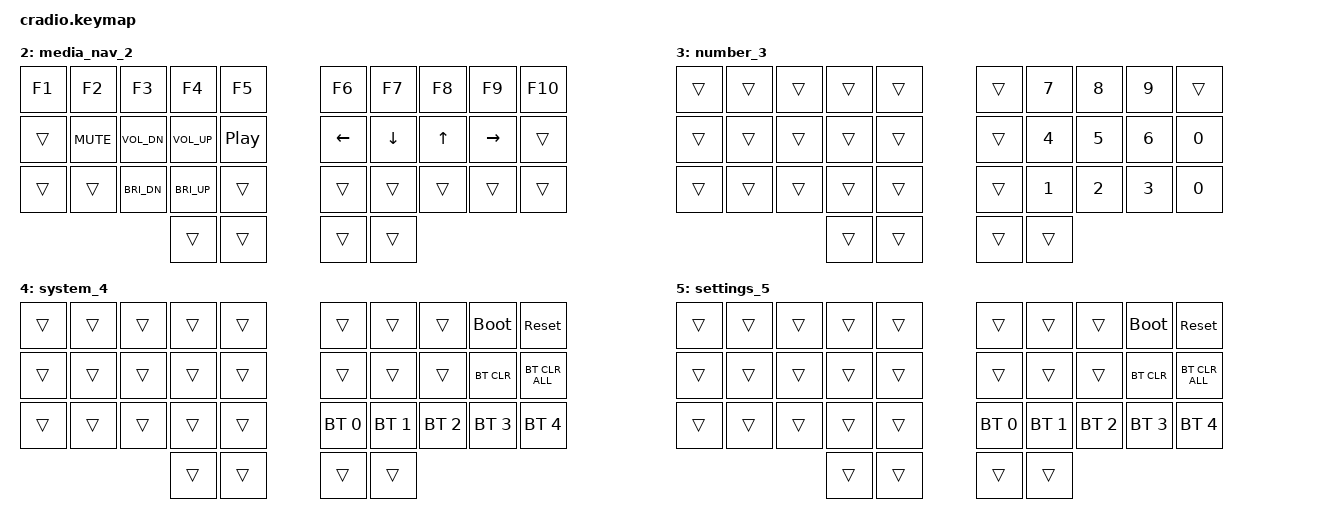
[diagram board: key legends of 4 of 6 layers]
// Copyright (c) 2022 The ZMK Contributors
// SPDX-License-Identifier: MIT

#include <behaviors.dtsi>
#include <dt-bindings/zmk/keys.h>
#include <dt-bindings/zmk/bt.h>

// Home row mods macro
#define HRML(k1,k2,k3,k4,k5) &ht LGUI k1  &ht LCTRL k2  &ht LALT k3  &ht LSHFT k4  &ht LA(LC(LG(LSHFT))) k5
#define HRMR(k1,k2,k3,k4,k5) &ht LA(LC(LG(LSHFT))) k1  &ht LSHFT k2  &ht LALT k3  &ht LCTRL k4  &ht LGUI k5
#define COMBO_0(NAME, BINDINGS, KEYPOS) \
  combo_##NAME { \
    timeout-ms = <50>; \
    bindings = <BINDINGS>; \
    key-positions = <KEYPOS>; \
    layers = <0>; \
  };
#define MACRO(NAME, BINDINGS) \
  macro_##NAME: macro_##NAME { \
    compatible     = "zmk,behavior-macro"; \
    tap-ms         = <1>; \
    wait-ms        = <1>; \
    #binding-cells = <0>; \
    bindings       = <&macro_tap BINDINGS>; \
  };

/ {
    behaviors {
        ht: hold_tap {
            compatible = "zmk,behavior-hold-tap";
            #binding-cells = <2>;
            flavor = "tap-preferred";
            tapping-term-ms = <200>;
            quick-tap-ms = <170>;
            require-prior-idle-ms = <125>;
            bindings = <&kp>, <&kp>;
        };

        lht: layer_hold_tap {
            compatible = "zmk,behavior-hold-tap";
            #binding-cells = <2>;
            flavor = "tap-preferred";
            tapping-term-ms = <200>;
            quick-tap-ms = <170>;
            require-prior-idle-ms = <125>;
            bindings = <&mo>, <&kp>;
        };

        // st: shift_tap {
        //     compatible = "zmk,behavior-mod-morph";
        //     #binding-cells = <0>;
        //     bindings = <&kp>, <&kp>;
        //     mods = <(MOD_LSFT|MOD_RSFT)>;
        // };

        td_quotes: tap_dance_quotes {
            compatible = "zmk,behavior-tap-dance";
            #binding-cells = <0>;
            tapping-term-ms = <250>;
            bindings = <&kp SINGLE_QUOTE>, <&kp DOUBLE_QUOTES>, <&kp GRAVE>;
        };
    };

    macros {
        MACRO(arrow, &kp MINUS &kp GT)
        MACRO(fat_arrow, &kp EQUAL &kp GT)
    };
    
    combos {
        compatible = "zmk,combos";
        COMBO_0(settings, &sl 5, 30 31)
        COMBO_0(fat_arrow, &macro_fat_arrow, 27 28)
        COMBO_0(left_square_bracket, &kp LBKT, 1 3)
        COMBO_0(right_square_bracket, &kp RBKT, 6 8)
        COMBO_0(left_parentesis, &kp LPAR, 11 13)
        COMBO_0(right_parentesis, &kp RPAR, 16 18)
        COMBO_0(left_bracket, &kp LBRC, 21 23)
        COMBO_0(right_bracket, &kp RBRC, 26 28)
        COMBO_0(escape, &kp ESCAPE, 16 17)
        // COMBO_0(quote, &kp SINGLE_QUOTE, 11 12)
        COMBO_0(quote, &td_quotes, 11 12)
        COMBO_0(colon, &kp COLON, 17 18)
        COMBO_0(letter_q, &kp Q, 1 2)
        COMBO_0(letter_p, &kp P, 7 8)
    };  

    // conditional_layers {
    //   compatible = "zmk,conditional-layers";
    //   tri_layer {
    //       if-layers = <1 2>;
    //       then-layer = <3>;
    //   };
    // };

    keymap {
        compatible = "zmk,keymap";
        main_0 {
            bindings = <
        //╭──────────┬──────────┬──────────┬──────────┬──────────╮   ╭──────────┬──────────┬──────────┬──────────┬──────────╮
        //│  Q       │  W       │  E       │  R       │  T       │   │  Y       │  U       │  I       │  O       │  P       │
            &kp Q      &kp W      &kp E      &kp R      &kp T          &kp Y      &kp U      &kp I      &kp O      &kp P
        //├──────────┼──────────┼──────────┼──────────┼──────────┤   ├──────────┼──────────┼──────────┼──────────┼──────────┤
        //│  A       │  S       │  D       │  F       │  G       │   │  H       │  J       │  K       │  L       │   ;      │
            HRML(A,        S,         D,         F,         G)          HRMR(H,       J,         K,          L,     SEMI)
        //├──────────┼──────────┼──────────┼──────────┼──────────┤   ├──────────┼──────────┼──────────┼──────────┼──────────┤
        //│  Z       │  X       │  C       │  V       │  B       │   │  N       │  M       │ , <      │ . >      │ / ?      │
            &kp Z      &kp X      &kp C      &kp V      &kp B          &kp N      &kp M      &kp COMMA  &kp DOT    &kp FSLH
        //╰──────────┴──────────┴──────────┼──────────┼──────────┤   ├──────────┼──────────┼──────────┴──────────┴──────────╯
                                            &lht 1 TAB  &lht 4 ENTER  &lht 3 SPACE  &lht 2 BSPC
        //                                 ╰──────────┴──────────╯   ╰──────────┴──────────╯
            >;
        };

        sym_1 {
            bindings = <
        //╭──────────┬──────────┬──────────┬──────────┬──────────╮   ╭──────────┬──────────┬──────────┬──────────┬──────────╮
        //│          │    "     │    |     │    &     │          │   │   +      │  [       │  ]       │  ^       │  %       │
            &trans     &kp DQT    &kp PIPE   &kp AMPS   &trans         &kp PLUS   &kp LBKT  &kp RBKT   &kp CARET   &kp PRCNT
        //├──────────┼──────────┼──────────┼──────────┼──────────┤   ├──────────┼──────────┼──────────┼──────────┼──────────┤
        //│  !       │  @       │  #       │  $       │  =       │   │ -        │  (       │  )       │  *       │  '       │
            HRML(EXCL,     AT,       HASH,      DLLR,      EQUAL)     HRMR(MINUS,    LPAR,      RPAR,      ASTRK, SINGLE_QUOTE)  
        //├──────────┼──────────┼──────────┼──────────┼──────────┤   ├──────────┼──────────┼──────────┼──────────┼──────────┤
        //│          │  CAPS    │  RALT    │  ESC     │          │   │ _        │  {       │  }       │  `       │  \       │
           &trans     &caps_word  &kp RALT   &kp ESCAPE  &trans       &kp UNDER   &kp LBRC   &kp RBRC   &kp GRAVE   &kp BSLH
        //╰──────────┴──────────┴──────────┼──────────┼──────────┤   ├──────────┼──────────┼──────────┴──────────┴──────────╯
                                             &trans     &trans         &trans     &trans
        //                                 ╰──────────┴──────────╯   ╰──────────┴──────────╯
            >;
        };

        media_nav_2 {
            bindings = <
        //╭──────────┬──────────┬──────────┬──────────┬──────────╮   ╭──────────┬──────────┬──────────┬──────────┬──────────╮
        //│  F1      │  F2      │  F3      │  F4      │  F5      │   │  F6      │  F7      │  F8      │  F9      │  F10     │
            &kp F1     &kp F2     &kp F3     &kp F4     &kp F5         &kp F6     &kp F7     &kp F8     &kp F9     &kp F10
        //├──────────┼──────────┼──────────┼──────────┼──────────┤   ├──────────┼──────────┼──────────┼──────────┼──────────┤
        //│          │ MUTE     │ VOL d    │ VOL u    │ PLY/PSE  │   │  LEFT    │  DOWN    │  UP      │  RIGHT   │ R Click  │
           &trans   &kp C_MUTE  &kp C_VOL_DN  &kp C_VOL_UP  &kp C_PP   &kp LEFT   &kp DOWN   &kp UP    &kp RIGHT  &trans
        //├──────────┼──────────┼──────────┼──────────┼──────────┤   ├──────────┼──────────┼──────────┼──────────┼──────────┤
        //│          │          │ BRGHT d  │ BRGHT u  │          │   │          │          │          │          │ L Click  │
            &trans    &trans     &kp C_BRI_DN  &kp C_BRI_UP  &trans    &trans     &trans     &trans     &trans     &trans
        //╰──────────┴──────────┴──────────┼──────────┼──────────┤   ├──────────┼──────────┼──────────┴──────────┴──────────╯
                                             &trans     &trans         &trans     &trans
        //                                 ╰──────────┴──────────╯   ╰──────────┴──────────╯
            >;
        };

        number_3 {
            bindings = <
        //╭──────────┬──────────┬──────────┬──────────┬──────────╮   ╭──────────┬──────────┬──────────┬──────────┬──────────╮
        //│          │          │          │          │          │   │          │  7       │  8       │  9       │          │
            &trans     &trans     &trans     &trans     &trans         &trans     &kp N7     &kp N8     &kp N9     &trans
        //├──────────┼──────────┼──────────┼──────────┼──────────┤   ├──────────┼──────────┼──────────┼──────────┼──────────┤
        //│          │          │          │          │          │   │          │  4       │  5       │  6       │  0       │
            &trans     &trans     &trans     &trans     &trans         &trans     &kp N4     &kp N5     &kp N6     &kp N0   
        //├──────────┼──────────┼──────────┼──────────┼──────────┤   ├──────────┼──────────┼──────────┼──────────┼──────────┤
        //│          │          │          │          │          │   │          │  1       │  2       │  3       │  0       │
            &trans     &trans     &trans     &trans     &trans         &trans     &kp N1     &kp N2     &kp N3     &kp N0
        //╰──────────┴──────────┴──────────┼──────────┼──────────┤   ├──────────┼──────────┼──────────┴──────────┴──────────╯
                                             &trans     &trans         &trans     &trans
        //                                 ╰──────────┴──────────╯   ╰──────────┴──────────╯
            >;
        };

        system_4 {
            bindings = <
        //╭──────────┬──────────┬──────────┬──────────┬──────────╮   ╭──────────┬──────────┬──────────┬──────────┬──────────╮
        //│          │          │          │          │          │   │          │          │          │          │          │
            &trans     &trans     &trans     &trans     &trans         &trans     &trans     &trans    &bootloader  &sys_reset
        //├──────────┼──────────┼──────────┼──────────┼──────────┤   ├──────────┼──────────┼──────────┼──────────┼──────────┤
        //│          │          │          │          │          │   │          │          │          │  BT Clr  │BT Clr all│
            &trans     &trans     &trans     &trans     &trans         &trans     &trans     &trans    &bt BT_CLR  &bt BT_CLR_ALL   
        //├──────────┼──────────┼──────────┼──────────┼──────────┤   ├──────────┼──────────┼──────────┼──────────┼──────────┤
        //│          │          │          │          │          │   │  BT 0    │  BT 1    │  BT 2    │  BT 3    │  BT 4    │
            &trans     &trans     &trans     &trans     &trans      &bt BT_SEL 0  &bt BT_SEL 1  &bt BT_SEL 2  &bt BT_SEL 3  &bt BT_SEL 4
        //╰──────────┴──────────┴──────────┼──────────┼──────────┤   ├──────────┼──────────┼──────────┴──────────┴──────────╯
                                             &trans     &trans         &trans     &trans
        //                                 ╰──────────┴──────────╯   ╰──────────┴──────────╯
            >;
        };

        settings_5 {
            bindings = <
        //╭──────────┬──────────┬──────────┬──────────┬──────────╮   ╭──────────┬──────────┬──────────┬──────────┬──────────╮
        //│          │          │          │          │          │   │          │          │          │          │          │
            &trans     &trans     &trans     &trans     &trans         &trans     &trans     &trans    &bootloader  &sys_reset
        //├──────────┼──────────┼──────────┼──────────┼──────────┤   ├──────────┼──────────┼──────────┼──────────┼──────────┤
        //│          │          │          │          │          │   │          │          │          │  BT Clr  │BT Clr all│
            &trans     &trans     &trans     &trans     &trans         &trans     &trans     &trans    &bt BT_CLR  &bt BT_CLR_ALL   
        //├──────────┼──────────┼──────────┼──────────┼──────────┤   ├──────────┼──────────┼──────────┼──────────┼──────────┤
        //│          │          │          │          │          │   │  BT 0    │  BT 1    │  BT 2    │  BT 3    │  BT 4    │
            &trans     &trans     &trans     &trans     &trans      &bt BT_SEL 0  &bt BT_SEL 1  &bt BT_SEL 2  &bt BT_SEL 3  &bt BT_SEL 4
        //╰──────────┴──────────┴──────────┼──────────┼──────────┤   ├──────────┼──────────┼──────────┴──────────┴──────────╯
                                             &trans     &trans         &trans     &trans
        //                                 ╰──────────┴──────────╯   ╰──────────┴──────────╯
            >;
        };
    };
};
